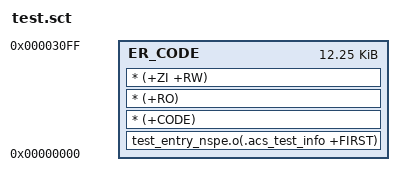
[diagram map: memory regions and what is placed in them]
/* Copyright (c) 2018-2019, Arm Limited or its affiliates. All rights reserved.
 * SPDX-License-Identifier : Apache-2.0
 *
 * Licensed under the Apache License, Version 2.0 (the "License");
 * you may not use this file except in compliance with the License.
 * You may obtain a copy of the License at
 *
 *  http://www.apache.org/licenses/LICENSE-2.0
 *
 * Unless required by applicable law or agreed to in writing, software
 * distributed under the License is distributed on an "AS IS" BASIS,
 * WITHOUT WARRANTIES OR CONDITIONS OF ANY KIND, either express or implied.
 * See the License for the specific language governing permissions and
 * limitations under the License.
**/

#define TEST_CODE_START 0x0
#define TEST_INFO_SIZE  0x100
#define TEST_TEXT_SIZE  0x1800
#define TEST_DATA_SIZE  0x1800

LR_CODE TEST_CODE_START
{

    ER_CODE TEST_CODE_START (TEST_INFO_SIZE+TEST_TEXT_SIZE+TEST_DATA_SIZE)
    {
        test_entry_nspe.o(.acs_test_info +FIRST)
        * (+CODE)
        * (+RO)
        * (+ZI +RW)
    }

}
